VERSION ""

NS_ :

BS_:

BU_: EON EPAS TOYOTASAS SMART
VAL_TABLE_ BRAKEMODE 3 "Reserved" 2 "Position Control" 1 "Relative Control" 0 "Disengadged" ;
VAL_TABLE_ STATUS 5 "FAULT_TIMEOUT" 4 "FAULT_STARTUP" 3 "FAULT_SCE" 2 "FAULT_SEND" 1 "FAULT_BAD_CHECKSUM" 0 "NO_FAULT" ;
VAL_TABLE_ STEERINGMODE 3 "Reserved" 2 "Position Control" 1 "Torque Control" 0 "Disengadged" ;
VAL_TABLE_ YESNO 1 "Yes" 0 "No" ;

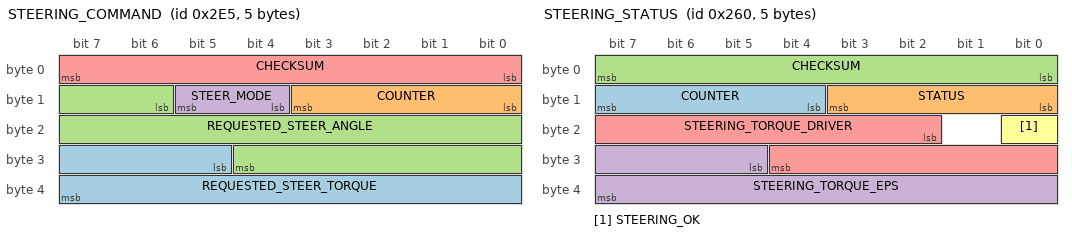
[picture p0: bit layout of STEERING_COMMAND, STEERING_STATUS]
BO_ 741 STEERING_COMMAND: 5 EON
 SG_ REQUESTED_STEER_TORQUE : 29|11@1- (0.5,0) [-512|511.5] "Nm" EPAS
 SG_ COUNTER : 8|4@1+ (1,0) [0|15] "" EPAS
 SG_ REQUESTED_STEER_ANGLE : 14|15@1- (0.1,0) [-1638.4|1638.3] "deg" EPAS
 SG_ STEER_MODE : 12|2@1+ (1,0) [0|3] "" EPAS
 SG_ CHECKSUM : 0|8@1+ (1,0) [0|255] "" EPAS

BO_ 608 STEERING_STATUS: 5 EPAS
 SG_ COUNTER : 12|4@1+ (1,0) [0|15] "" EON
 SG_ STATUS : 11|4@0+ (1,0) [0|15] "" EON
 SG_ CHECKSUM : 0|8@1+ (1,0) [0|255] "" EON
 SG_ STEERING_TORQUE_EPS : 29|11@1- (0.8,0) [-819.2|818.4] "Nm" EON
 SG_ STEERING_TORQUE_DRIVER : 18|11@1- (0.8,0) [-819.2|818.4] "Nm" EON
 SG_ STEERING_OK : 16|1@1+ (1,0) [0|1] "" EON

BO_ 1585 SMART_ROADSTER_MESSAGE8: 8 SMART

BO_ 1301 SMART_ROADSTER_MESSAGE7: 7 SMART

BO_ 816 SMART_ROADSTER_MESSAGE6: 2 SMART

BO_ 768 SMART_ROADSTER_MESSAGE5: 8 SMART

BO_ 570 SMART_ROADSTER_MESSAGE4: 8 SMART

BO_ 568 SMART_ROADSTER_MESSAGE3: 8 SMART

BO_ 528 SMART_ROADSTER_MESSAGE2: 8 SMART

BO_ 128 SMART_ROADSTER_MESSAGE1: 8 SMART

BO_ 1059 TOYOTA_STEERING_ANGLE_SENSOR3: 1 TOYOTASAS

BO_ 1222 TOYOTA_STEERING_ANGLE_SENSOR2: 8 TOYOTASAS

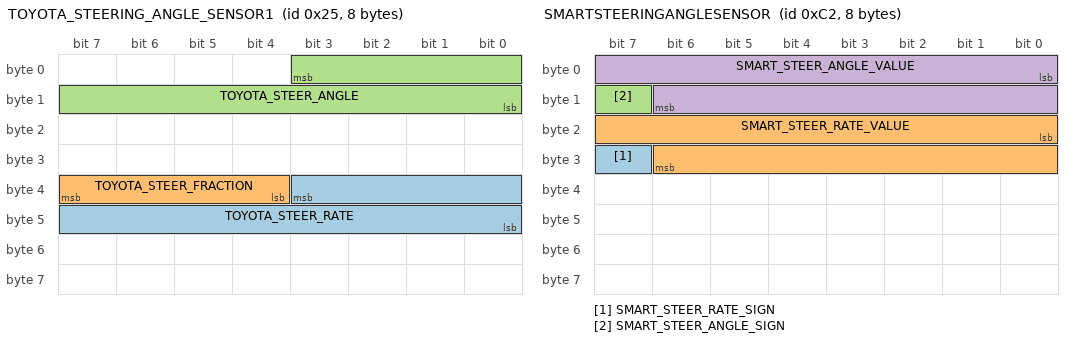
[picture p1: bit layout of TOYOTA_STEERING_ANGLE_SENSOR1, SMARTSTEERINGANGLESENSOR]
BO_ 37 TOYOTA_STEERING_ANGLE_SENSOR1: 8 TOYOTASAS
 SG_ TOYOTA_STEER_RATE : 35|12@0- (1,0) [-2000|2000] "deg/s" EON
 SG_ TOYOTA_STEER_FRACTION : 39|4@0- (0.1,0) [-0.7|0.7] "deg" EON
 SG_ TOYOTA_STEER_ANGLE : 3|12@0- (1.5,0) [-500|500] "deg" EON

BO_ 194 SMARTSTEERINGANGLESENSOR: 8 SMART
 SG_ SMART_STEER_RATE_SIGN : 31|1@1+ (1,0) [0|0] "" EON
 SG_ SMART_STEER_RATE_VALUE : 16|15@1+ (0.04375,0) [0|1433.6] "Deg/S" EON
 SG_ SMART_STEER_ANGLE_SIGN : 15|1@1+ (1,0) [0|0] "" EON
 SG_ SMART_STEER_ANGLE_VALUE : 0|15@1+ (0.04375,0) [0|1433.6] "Deg" EON

BO_ 784 SMARTTHROTTLEPEDAL: 8 SMART
 SG_ THROTTLE_POSITION : 32|16@1+ (0.00156143,0) [0|0] "%" EON

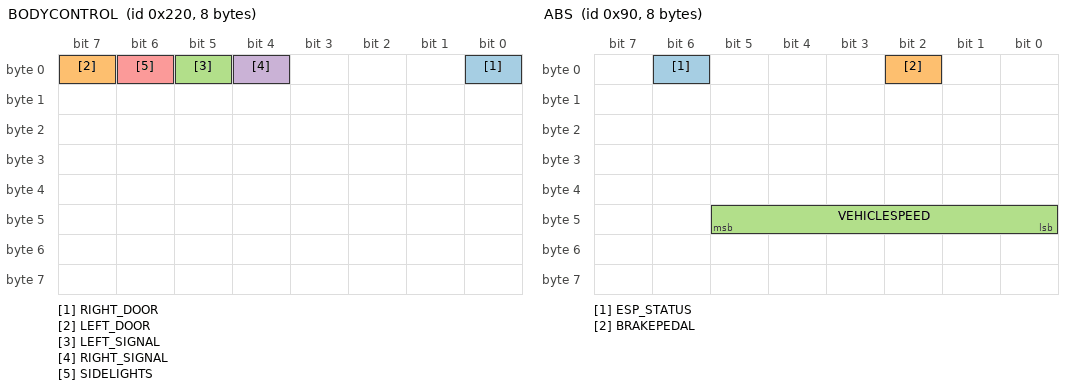
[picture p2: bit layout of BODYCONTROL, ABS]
BO_ 544 BODYCONTROL: 8 SMART
 SG_ RIGHT_DOOR : 0|1@1+ (1,0) [0|0] "" EON
 SG_ LEFT_DOOR : 7|1@1+ (1,0) [0|0] "" EON
 SG_ LEFT_SIGNAL : 5|1@1+ (1,0) [0|0] "" EON
 SG_ RIGHT_SIGNAL : 4|1@1+ (1,0) [0|0] "" EON
 SG_ SIDELIGHTS : 6|1@1+ (1,0) [0|0] "" EON

BO_ 144 ABS: 8 SMART
 SG_ ESP_STATUS : 6|1@1+ (1,0) [0|0] "" EON
 SG_ BRAKEPEDAL : 2|1@1+ (1,0) [0|0] "" EON
 SG_ VEHICLESPEED : 45|6@0- (1,0) [0|0] "mph" EON

BO_ 400 Gearbox: 8 SMART
 SG_ GEARPOSITION : 0|8@1+ (1,0) [0|0] "" EON

BO_ 520 WHEELSPEEDS: 8 SMART
 SG_ WHEELSPEED_FR : 40|7@1- (1,0) [0|0] "mph" EON
 SG_ WHEELSPEED_FL : 48|7@1- (1,0) [0|0] "mph" EON

CM_ SG_ 741 CHECKSUM "CRC8_J1650 SAE Checksum";
CM_ SG_ 608 CHECKSUM "CRC8_J1650 SAE Checksum";
BA_DEF_ BO_  "GenMsgBackgroundColor" STRING ;
BA_DEF_ BO_  "GenMsgForegroundColor" STRING ;
BA_DEF_DEF_  "GenMsgBackgroundColor" "#1e1e1e";
BA_DEF_DEF_  "GenMsgForegroundColor" "#ffffff";

VAL_ 741 STEER_MODE 3 "Reserved" 2 "Position Control" 1 "Torque Control" 0 "Disengadged" ;
VAL_ 608 STATUS 5 "FAULT_TIMEOUT" 4 "FAULT_STARTUP" 3 "FAULT_SCE" 2 "FAULT_SEND" 1 "FAULT_BAD_CHECKSUM" 0 "NO_FAULT" ;
VAL_ 608 STEERING_OK 1 "Yes" 0 "No" ;
VAL_ 544 RIGHT_DOOR 0 "Open" 1 "Closed" ;
VAL_ 544 LEFT_DOOR 0 "Open" 1 "Closed" ;
VAL_ 544 LEFT_SIGNAL 0 "Off" 1 "On" ;
VAL_ 544 RIGHT_SIGNAL 0 "Off" 1 "On" ;
VAL_ 544 SIDELIGHTS 0 "Off" 1 "On" ;
VAL_ 144 ESP_STATUS 0 "On" 1 "Off" ;
VAL_ 144 BRAKEPEDAL 0 "Not_pressed" 1 "Pressed" ;
VAL_ 400 GEARPOSITION 8 "Neutral" 4 "Reverse" 76 "Auto" 16 "Manual" ;
